# ATxmega256D3 device description
Architecture: AVR8_XMEGA; Family: AVR XMEGA
Registers are 8-bit, access not given, no defined reset value unless marked. A register's access mark holds for its fields unless they carry their own. Offsets are from the block's base; [hi:lo] are bit positions; {n}, {i} and the like mark numbered series; 'fields as' and 'values as' point back to an identical list.

## PORTCFG — I/O port Configuration
Instances: PORTCFG 0x00B0
0x00 MPCMASK — Multi-pin Configuration Mask
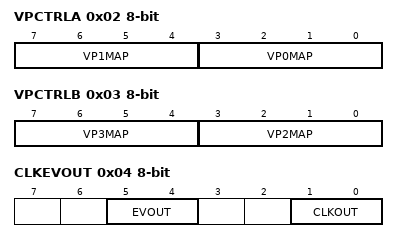
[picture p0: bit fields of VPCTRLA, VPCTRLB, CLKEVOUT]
0x02 VPCTRLA — Virtual Port Control Register A
  [7:4] VP1MAP — Virtual Port 1 Mapping
    0=PORTA (Mapped To PORTA); 1=PORTB (Mapped To PORTB); 2=PORTC (Mapped To PORTC); 3=PORTD (Mapped To PORTD); 4=PORTE (Mapped To PORTE); 5=PORTF (Mapped To PORTF); 6=PORTG (Mapped To PORTG); 7=PORTH (Mapped To PORTH); 8=PORTJ (Mapped To PORTJ); 9=PORTK (Mapped To PORTK); 10=PORTL (Mapped To PORTL); 11=PORTM (Mapped To PORTM); 12=PORTN (Mapped To PORTN); 13=PORTP (Mapped To PORTP); 14=PORTQ (Mapped To PORTQ); 15=PORTR (Mapped To PORTR)
  [3:0] VP0MAP — Virtual Port 0 Mapping
    values as VP1MAP
0x03 VPCTRLB — Virtual Port Control Register B
  [7:4] VP3MAP — Virtual Port 3 Mapping
    values as VPCTRLA.VP1MAP
  [3:0] VP2MAP — Virtual Port 2 Mapping
    values as VPCTRLA.VP1MAP
0x04 CLKEVOUT — Clock and Event Out Register
  [5:4] EVOUT — Event Output Port
    0=OFF (Event Output Disabled); 1=PC7 (Event Channel 7 Output on Port C pin 7); 2=PD7 (Event Channel 7 Output on Port D pin 7); 3=PE7 (Event Channel 7 Output on Port E pin 7)
  [1:0] CLKOUT — Clock Output Port
    0=OFF (Clock Output Disabled); 1=PC7 (Clock Output on Port C pin 7); 2=PD7 (Clock Output on Port D pin 7); 3=PE7 (Clock Output on Port E pin 7)

## VPORT — Virtual Port
Instances: VPORT{n} {0x10+4n} (n=0..3)
0x00 DIR — I/O Port Data Direction
0x01 OUT — I/O Port Output
0x02 IN — I/O Port Input
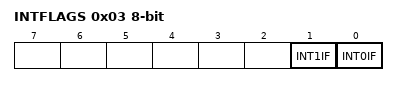
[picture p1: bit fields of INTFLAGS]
0x03 INTFLAGS — Interrupt Flag Register
  [1] INT1IF — Port Interrupt 1 Flag
  [0] INT0IF — Port Interrupt 0 Flag

## PORT — I/O Ports
Instances: PORTA 0x0600, PORTB 0x0620, PORTC 0x0640, PORTD 0x0660, PORTE 0x0680, PORTF 0x06A0, PORTR 0x07E0
0x00 DIR — I/O Port Data Direction
0x01 DIRSET — I/O Port Data Direction Set
0x02 DIRCLR — I/O Port Data Direction Clear
0x03 DIRTGL — I/O Port Data Direction Toggle
0x04 OUT — I/O Port Output
0x05 OUTSET — I/O Port Output Set
0x06 OUTCLR — I/O Port Output Clear
0x07 OUTTGL — I/O Port Output Toggle
0x08 IN — I/O port Input
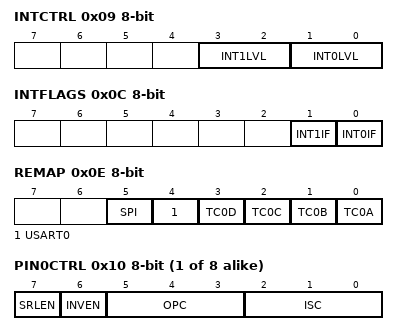
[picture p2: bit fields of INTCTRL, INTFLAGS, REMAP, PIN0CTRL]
0x09 INTCTRL — Interrupt Control Register
  [3:2] INT1LVL — Port Interrupt 1 Level
    0=OFF (Interrupt Disabled); 1=LO (Low Level); 2=MED (Medium Level); 3=HI (High Level)
  [1:0] INT0LVL — Port Interrupt 0 Level
    values as INT1LVL
0x0A INT0MASK — Port Interrupt 0 Mask
0x0B INT1MASK — Port Interrupt 1 Mask
0x0C INTFLAGS — Interrupt Flag Register
  [1] INT1IF — Port Interrupt 1 Flag
  [0] INT0IF — Port Interrupt 0 Flag
0x0E REMAP — Pin Remap Register (available for PORTC to PORTF only)
  [5] SPI — SPI Remap
  [4] USART0 — USART0 Remap
  [3] TC0D — Timer/Counter 0 Output Compare D
  [2] TC0C — Timer/Counter 0 Output Compare C
  [1] TC0B — Timer/Counter 0 Output Compare B
  [0] TC0A — Timer/Counter 0 Output Compare A
{0x10+i} PIN{i}CTRL (i=0..7) — Pin {i} Control Register
  [7] SRLEN — Slew Rate Enable
  [6] INVEN — Inverted I/O Enable
  [5:3] OPC — Output/Pull Configuration
    0=TOTEM (Totempole); 1=BUSKEEPER (Totempole w/ Bus keeper on Input and Output); 2=PULLDOWN (Totempole w/ Pull-down on Input); 3=PULLUP (Totempole w/ Pull-up on Input); 4=WIREDOR; 5=WIREDAND; 6=WIREDORPULL (Wired OR w/ Pull-down); 7=WIREDANDPULL (Wired AND w/ Pull-up)
  [2:0] ISC — Input/Sense Configuration
    0=BOTHEDGES (Sense Both Edges); 1=RISING (Sense Rising Edge); 2=FALLING (Sense Falling Edge); 3=LEVEL (Sense Level (Transparent For Events)); 7=INPUT_DISABLE (Disable Digital Input Buffer)

## AWEX (TC module) — Advanced Waveform Extension
Instances: AWEXC 0x880, AWEXE 0xA80
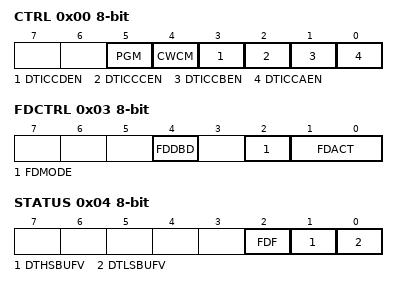
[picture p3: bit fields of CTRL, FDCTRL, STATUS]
0x00 CTRL — Control Register
  [5] PGM — Pattern Generation Mode
  [4] CWCM — Common Waveform Channel Mode
  [3] DTICCDEN — Dead Time Insertion Compare Channel D Enable
  [2] DTICCCEN — Dead Time Insertion Compare Channel C Enable
  [1] DTICCBEN — Dead Time Insertion Compare Channel B Enable
  [0] DTICCAEN — Dead Time Insertion Compare Channel A Enable
0x02 FDEMASK — Fault Detection Event Mask
0x03 FDCTRL — Fault Detection Control Register
  [4] FDDBD — Fault Detect on Disable Break Disable
  [2] FDMODE — Fault Detect Mode
  [1:0] FDACT — Fault Detect Action
    0=NONE (No Fault Protection); 1=CLEAROE (Clear Output Enable Bits); 3=CLEARDIR (Clear I/O Port Direction Bits)
0x04 STATUS
  [2] FDF — Fault Detect Flag
  [1] DTHSBUFV — Dead Time High Side Buffer Valid
  [0] DTLSBUFV — Dead Time Low Side Buffer Valid
0x06 DTBOTH — Dead Time Both Sides
0x07 DTBOTHBUF — Dead Time Both Sides Buffer
0x08 DTLS — Dead Time Low Side
0x09 DTHS — Dead Time High Side
0x0A DTLSBUF — Dead Time Low Side Buffer
0x0B DTHSBUF — Dead Time High Side Buffer
0x0C OUTOVEN — Output Override Enable

## HIRES (TC module) — High-Resolution Extension
Instances: HIRESC 0x890
0x00 CTRLA — Control Register
  [1:0] HREN — High Resolution Enable
    0=NONE (No Fault Protection); 1=TC0 (Enable High Resolution on Timer/Counter 0); 2=TC1 (Enable High Resolution on Timer/Counter 1); 3=BOTH (Enable High Resolution both Timer/Counters)

## USART — Universal Synchronous/Asynchronous Receiver/Transmitter
Instances: USARTC0 0x8A0, USARTD0 0x9A0, USARTE0 0xAA0
0x00 DATA
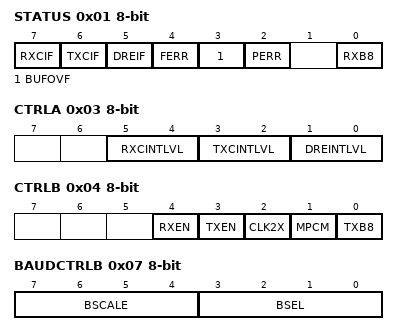
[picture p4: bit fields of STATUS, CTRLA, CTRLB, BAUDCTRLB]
0x01 STATUS
  [7] RXCIF — Receive Interrupt Flag
  [6] TXCIF — Transmit Interrupt Flag
  [5] DREIF — Data Register Empty Flag
  [4] FERR — Frame Error
  [3] BUFOVF — Buffer Overflow
  [2] PERR — Parity Error
  [0] RXB8 — Receive Bit 8
0x03 CTRLA — Control Register A
  [all] fields
    0=OFF (Interrupt Disabled); 1=LO (Low Level); 2=MED (Medium Level); 3=HI (High Level)
  [5:4] RXCINTLVL — Receive Interrupt Level
  [3:2] TXCINTLVL — Transmit Interrupt Level
  [1:0] DREINTLVL — Data Register Empty Interrupt Level
0x04 CTRLB — Control Register B
  [4] RXEN — Receiver Enable
  [3] TXEN — Transmitter Enable
  [2] CLK2X — Double transmission speed
  [1] MPCM — Multi-processor Communication Mode
  [0] TXB8 — Transmit bit 8
0x05 CTRLC — Control Register C
  [7:6] CMODE — Communication Mode
    0=ASYNCHRONOUS (Asynchronous Mode); 1=SYNCHRONOUS (Synchronous Mode); 2=IRDA (IrDA Mode); 3=MSPI (Master SPI Mode)
  [5:4] PMODE — Parity Mode
    0=DISABLED (No Parity); 2=EVEN (Even Parity); 3=ODD (Odd Parity)
  [3] SBMODE — Stop Bit Mode
  [2] UDORD — SPI Master Mode, Data Order
  [1] UCPHA — SPI Master Mode, Clock Phase
  [2:0] CHSIZE — Character Size
    {v}={v+5}BIT (Character size: {v+5} bit) (v=0..3); 7=9BIT (Character size: 9 bit)
0x06 BAUDCTRLA — Baud Rate Control Register A
  [7:0] BSEL — Baud Rate Selection Bits [7:0]
0x07 BAUDCTRLB — Baud Rate Control Register B
  [7:4] BSCALE — Baud Rate Scale
  [3:0] BSEL — Baud Rate Selection bits[11:8]

## SPI — Serial Peripheral Interface
Instances: SPIC 0x8C0, SPID 0x9C0, SPIE 0xAC0
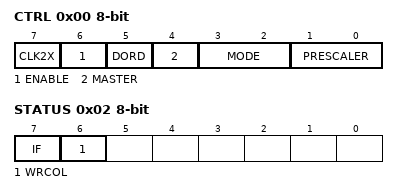
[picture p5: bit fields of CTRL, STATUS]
0x00 CTRL — Control Register
  [7] CLK2X — Enable Double Speed
  [6] ENABLE — Enable Module
  [5] DORD — Data Order Setting
  [4] MASTER — Master Operation Enable
  [3:2] MODE — SPI Mode
    {v}=SPI Mode {v} (v=0..3)
  [1:0] PRESCALER
    0=DIV4 (System Clock / 4); 1=DIV16 (System Clock / 16); 2=DIV64 (System Clock / 64); 3=DIV128 (System Clock / 128)
0x01 INTCTRL — Interrupt Control Register
  [1:0] INTLVL — Interrupt level
    0=OFF (Interrupt Disabled); 1=LO (Low Level); 2=MED (Medium Level); 3=HI (High Level)
0x02 STATUS
  [7] IF — Interrupt Flag
  [6] WRCOL — Write Collision
0x03 DATA

## IRCOM — IR Communication Module
Instances: IRCOM 0x8F8
0x00 CTRL — Control Register
  [3:0] EVSEL — Event Channel Select
    0=OFF (No Event Source); {v}=Event Channel {v-8} (v=8..15)
0x01 TXPLCTRL — IrDA Transmitter Pulse Length Control Register
0x02 RXPLCTRL — IrDA Receiver Pulse Length Control Register
